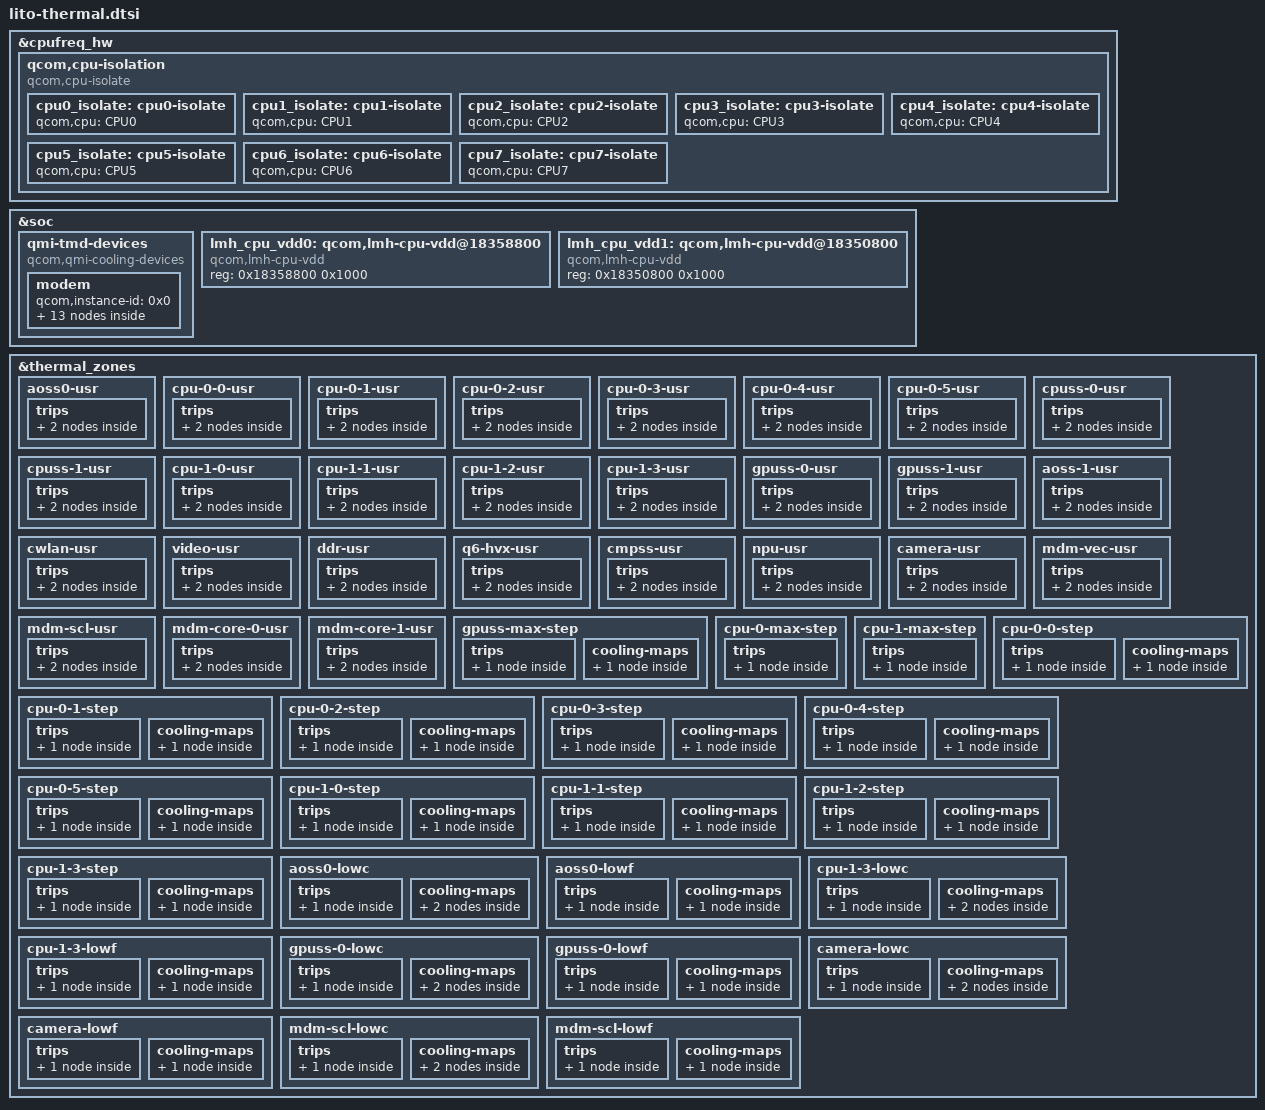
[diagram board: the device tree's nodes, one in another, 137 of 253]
#include <dt-bindings/thermal/thermal.h>

&cpufreq_hw {
	qcom,cpu-isolation {
		compatible = "qcom,cpu-isolate";
		cpu0_isolate: cpu0-isolate {
			qcom,cpu = <&CPU0>;
			#cooling-cells = <2>;
		};

		cpu1_isolate: cpu1-isolate {
			qcom,cpu = <&CPU1>;
			#cooling-cells = <2>;
		};

		cpu2_isolate: cpu2-isolate {
			qcom,cpu = <&CPU2>;
			#cooling-cells = <2>;
		};

		cpu3_isolate: cpu3-isolate {
			qcom,cpu = <&CPU3>;
			#cooling-cells = <2>;
		};

		cpu4_isolate: cpu4-isolate {
			qcom,cpu = <&CPU4>;
			#cooling-cells = <2>;
		};

		cpu5_isolate: cpu5-isolate {
			qcom,cpu = <&CPU5>;
			#cooling-cells = <2>;
		};

		cpu6_isolate: cpu6-isolate {
			qcom,cpu = <&CPU6>;
			#cooling-cells = <2>;
		};

		cpu7_isolate: cpu7-isolate {
			qcom,cpu = <&CPU7>;
			#cooling-cells = <2>;
		};
	};
};

&soc {
	qmi-tmd-devices {
		compatible = "qcom,qmi-cooling-devices";

		modem {
			qcom,instance-id = <0x0>;

			modem_pa: modem_pa {
				qcom,qmi-dev-name = "pa";
				#cooling-cells = <2>;
			};

			modem_proc: modem_proc {
				qcom,qmi-dev-name = "modem";
				#cooling-cells = <2>;
			};

			modem_current: modem_current {
				qcom,qmi-dev-name = "modem_current";
				#cooling-cells = <2>;
			};

			modem_skin: modem_skin {
				qcom,qmi-dev-name = "modem_skin";
				#cooling-cells = <2>;
			};

			modem_skin0: modem_skin0 {
				qcom,qmi-dev-name = "modem_skin0";
				#cooling-cells = <2>;
			};

			modem_skin1: modem_skin1 {
				qcom,qmi-dev-name = "modem_skin1";
				#cooling-cells = <2>;
			};

			modem_skin2: modem_skin2 {
				qcom,qmi-dev-name = "modem_skin2";
				#cooling-cells = <2>;
			};

			modem_skin3: modem_skin3 {
				qcom,qmi-dev-name = "modem_skin3";
				#cooling-cells = <2>;
			};

			modem_mmw0: modem_mmw0 {
				qcom,qmi-dev-name = "mmw0";
				#cooling-cells = <2>;
			};

			modem_mmw1: modem_mmw1 {
				qcom,qmi-dev-name = "mmw1";
				#cooling-cells = <2>;
			};

			modem_mmw2: modem_mmw2 {
				qcom,qmi-dev-name = "mmw2";
				#cooling-cells = <2>;
			};

			modem_mmw3: modem_mmw3 {
				qcom,qmi-dev-name = "mmw3";
				#cooling-cells = <2>;
			};

			modem_bcl: modem_bcl {
				qcom,qmi-dev-name = "vbatt_low";
				#cooling-cells = <2>;
			};
		};
	};

	lmh_cpu_vdd0: qcom,lmh-cpu-vdd@18358800 {
		compatible = "qcom,lmh-cpu-vdd";
		reg =  <0x18358800 0x1000>;
		#cooling-cells = <2>;
	};

	lmh_cpu_vdd1: qcom,lmh-cpu-vdd@18350800 {
		compatible = "qcom,lmh-cpu-vdd";
		reg =  <0x18350800 0x1000>;
		#cooling-cells = <2>;
	};

};

&thermal_zones {
	aoss0-usr {
		polling-delay-passive = <0>;
		polling-delay = <0>;
		thermal-governor = "user_space";
		thermal-sensors = <&tsens0 0>;
		wake-capable-sensor;
		trips {
			active-config0 {
				temperature = <125000>;
				hysteresis = <1000>;
				type = "passive";
			};

			reset-mon-config {
				temperature = <115000>;
				hysteresis = <1000>;
				type = "passive";
			};
		};
	};

	cpu-0-0-usr {
		polling-delay-passive = <0>;
		polling-delay = <0>;
		thermal-governor = "user_space";
		thermal-sensors = <&tsens0 1>;
		wake-capable-sensor;
		trips {
			active-config0 {
				temperature = <125000>;
				hysteresis = <1000>;
				type = "passive";
			};

			reset-mon-config {
				temperature = <115000>;
				hysteresis = <1000>;
				type = "passive";
			};
		};
	};

	cpu-0-1-usr {
		polling-delay-passive = <0>;
		polling-delay = <0>;
		thermal-governor = "user_space";
		thermal-sensors = <&tsens0 2>;
		wake-capable-sensor;
		trips {
			active-config0 {
				temperature = <125000>;
				hysteresis = <1000>;
				type = "passive";
			};

			reset-mon-config {
				temperature = <115000>;
				hysteresis = <1000>;
				type = "passive";
			};
		};
	};

	cpu-0-2-usr {
		polling-delay-passive = <0>;
		polling-delay = <0>;
		thermal-governor = "user_space";
		thermal-sensors = <&tsens0 3>;
		wake-capable-sensor;
		trips {
			active-config0 {
				temperature = <125000>;
				hysteresis = <1000>;
				type = "passive";
			};

			reset-mon-config {
				temperature = <115000>;
				hysteresis = <1000>;
				type = "passive";
			};
		};
	};

	cpu-0-3-usr {
		polling-delay-passive = <0>;
		polling-delay = <0>;
		thermal-sensors = <&tsens0 4>;
		thermal-governor = "user_space";
		wake-capable-sensor;
		trips {
			active-config0 {
				temperature = <125000>;
				hysteresis = <1000>;
				type = "passive";
			};

			reset-mon-config {
				temperature = <115000>;
				hysteresis = <1000>;
				type = "passive";
			};
		};
	};

	cpu-0-4-usr {
		polling-delay-passive = <0>;
		polling-delay = <0>;
		thermal-sensors = <&tsens0 5>;
		thermal-governor = "user_space";
		wake-capable-sensor;
		trips {
			active-config0 {
				temperature = <125000>;
				hysteresis = <1000>;
				type = "passive";
			};

			reset-mon-config {
				temperature = <115000>;
				hysteresis = <1000>;
				type = "passive";
			};
		};
	};

	cpu-0-5-usr {
		polling-delay-passive = <0>;
		polling-delay = <0>;
		thermal-sensors = <&tsens0 6>;
		thermal-governor = "user_space";
		wake-capable-sensor;
		trips {
			active-config0 {
				temperature = <125000>;
				hysteresis = <1000>;
				type = "passive";
			};

			reset-mon-config {
				temperature = <115000>;
				hysteresis = <1000>;
				type = "passive";
			};
		};
	};

	cpuss-0-usr {
		polling-delay-passive = <0>;
		polling-delay = <0>;
		thermal-sensors = <&tsens0 7>;
		thermal-governor = "user_space";
		wake-capable-sensor;
		trips {
			active-config0 {
				temperature = <125000>;
				hysteresis = <1000>;
				type = "passive";
			};

			reset-mon-config {
				temperature = <115000>;
				hysteresis = <1000>;
				type = "passive";
			};
		};
	};

	cpuss-1-usr {
		polling-delay-passive = <0>;
		polling-delay = <0>;
		thermal-sensors = <&tsens0 8>;
		thermal-governor = "user_space";
		wake-capable-sensor;
		trips {
			active-config0 {
				temperature = <125000>;
				hysteresis = <1000>;
				type = "passive";
			};

			reset-mon-config {
				temperature = <115000>;
				hysteresis = <1000>;
				type = "passive";
			};
		};
	};

	cpu-1-0-usr {
		polling-delay-passive = <0>;
		polling-delay = <0>;
		thermal-sensors = <&tsens0 9>;
		thermal-governor = "user_space";
		wake-capable-sensor;
		trips {
			active-config0 {
				temperature = <125000>;
				hysteresis = <1000>;
				type = "passive";
			};

			reset-mon-config {
				temperature = <115000>;
				hysteresis = <1000>;
				type = "passive";
			};
		};
	};

	cpu-1-1-usr {
		polling-delay-passive = <0>;
		polling-delay = <0>;
		thermal-sensors = <&tsens0 10>;
		thermal-governor = "user_space";
		wake-capable-sensor;
		trips {
			active-config0 {
				temperature = <125000>;
				hysteresis = <1000>;
				type = "passive";
			};

			reset-mon-config {
				temperature = <115000>;
				hysteresis = <1000>;
				type = "passive";
			};
		};
	};

	cpu-1-2-usr {
		polling-delay-passive = <0>;
		polling-delay = <0>;
		thermal-sensors = <&tsens0 11>;
		thermal-governor = "user_space";
		wake-capable-sensor;
		trips {
			active-config0 {
				temperature = <125000>;
				hysteresis = <1000>;
				type = "passive";
			};

			reset-mon-config {
				temperature = <115000>;
				hysteresis = <1000>;
				type = "passive";
			};
		};
	};

	cpu-1-3-usr {
		polling-delay-passive = <0>;
		polling-delay = <0>;
		thermal-sensors = <&tsens0 12>;
		thermal-governor = "user_space";
		wake-capable-sensor;
		trips {
			active-config0 {
				temperature = <125000>;
				hysteresis = <1000>;
				type = "passive";
			};

			reset-mon-config {
				temperature = <115000>;
				hysteresis = <1000>;
				type = "passive";
			};
		};
	};

	gpuss-0-usr {
		polling-delay-passive = <0>;
		polling-delay = <0>;
		thermal-sensors = <&tsens0 13>;
		thermal-governor = "user_space";
		wake-capable-sensor;
		trips {
			active-config0 {
				temperature = <125000>;
				hysteresis = <1000>;
				type = "passive";
			};

			reset-mon-config {
				temperature = <115000>;
				hysteresis = <1000>;
				type = "passive";
			};
		};
	};

	gpuss-1-usr {
		polling-delay-passive = <0>;
		polling-delay = <0>;
		thermal-sensors = <&tsens0 14>;
		thermal-governor = "user_space";
		wake-capable-sensor;
		trips {
			active-config0 {
				temperature = <125000>;
				hysteresis = <1000>;
				type = "passive";
			};

			reset-mon-config {
				temperature = <115000>;
				hysteresis = <1000>;
				type = "passive";
			};
		};
	};

	aoss-1-usr {
		polling-delay-passive = <0>;
		polling-delay = <0>;
		thermal-sensors = <&tsens1 0>;
		thermal-governor = "user_space";
		wake-capable-sensor;
		trips {
			active-config0 {
				temperature = <125000>;
				hysteresis = <1000>;
				type = "passive";
			};

			reset-mon-config {
				temperature = <115000>;
				hysteresis = <1000>;
				type = "passive";
			};
		};
	};

	cwlan-usr {
		polling-delay-passive = <0>;
		polling-delay = <0>;
		thermal-sensors = <&tsens1 1>;
		thermal-governor = "user_space";
		wake-capable-sensor;
		trips {
			active-config0 {
				temperature = <125000>;
				hysteresis = <1000>;
				type = "passive";
			};

			reset-mon-config {
				temperature = <115000>;
				hysteresis = <1000>;
				type = "passive";
			};
		};
	};

	video-usr {
		polling-delay-passive = <0>;
		polling-delay = <0>;
		thermal-sensors = <&tsens1 2>;
		thermal-governor = "user_space";
		wake-capable-sensor;
		trips {
			active-config0 {
				temperature = <125000>;
				hysteresis = <1000>;
				type = "passive";
			};

			reset-mon-config {
				temperature = <115000>;
				hysteresis = <1000>;
				type = "passive";
			};
		};
	};

	ddr-usr {
		polling-delay-passive = <0>;
		polling-delay = <0>;
		thermal-sensors = <&tsens1 3>;
		thermal-governor = "user_space";
		wake-capable-sensor;
		trips {
			active-config0 {
				temperature = <125000>;
				hysteresis = <1000>;
				type = "passive";
			};

			reset-mon-config {
				temperature = <115000>;
				hysteresis = <1000>;
				type = "passive";
			};
		};
	};

	q6-hvx-usr {
		polling-delay-passive = <0>;
		polling-delay = <0>;
		thermal-sensors = <&tsens1 4>;
		thermal-governor = "user_space";
		wake-capable-sensor;
		trips {
			active-config0 {
				temperature = <125000>;
				hysteresis = <1000>;
				type = "passive";
			};

			reset-mon-config {
				temperature = <115000>;
				hysteresis = <1000>;
				type = "passive";
			};
		};
	};

	cmpss-usr {
		polling-delay-passive = <0>;
		polling-delay = <0>;
		thermal-sensors = <&tsens1 5>;
		thermal-governor = "user_space";
		wake-capable-sensor;
		trips {
			active-config0 {
				temperature = <125000>;
				hysteresis = <1000>;
				type = "passive";
			};

			reset-mon-config {
				temperature = <115000>;
				hysteresis = <1000>;
				type = "passive";
			};
		};
	};

	npu-usr {
		polling-delay-passive = <0>;
		polling-delay = <0>;
		thermal-sensors = <&tsens1 6>;
		thermal-governor = "user_space";
		wake-capable-sensor;
		trips {
			active-config0 {
				temperature = <125000>;
				hysteresis = <1000>;
				type = "passive";
			};

			reset-mon-config {
				temperature = <115000>;
				hysteresis = <1000>;
				type = "passive";
			};
		};
	};

	camera-usr {
		polling-delay-passive = <0>;
		polling-delay = <0>;
		thermal-sensors = <&tsens1 7>;
		thermal-governor = "user_space";
		wake-capable-sensor;
		trips {
			active-config0 {
				temperature = <125000>;
				hysteresis = <1000>;
				type = "passive";
			};

			reset-mon-config {
				temperature = <115000>;
				hysteresis = <1000>;
				type = "passive";
			};
		};
	};

	mdm-vec-usr {
		polling-delay-passive = <0>;
		polling-delay = <0>;
		thermal-sensors = <&tsens1 8>;
		thermal-governor = "user_space";
		wake-capable-sensor;
		trips {
			active-config0 {
				temperature = <125000>;
				hysteresis = <1000>;
				type = "passive";
			};

			reset-mon-config {
				temperature = <115000>;
				hysteresis = <1000>;
				type = "passive";
			};
		};
	};

	mdm-scl-usr {
		polling-delay-passive = <0>;
		polling-delay = <0>;
		thermal-sensors = <&tsens1 9>;
		thermal-governor = "user_space";
		wake-capable-sensor;
		trips {
			active-config0 {
				temperature = <125000>;
				hysteresis = <1000>;
				type = "passive";
			};

			reset-mon-config {
				temperature = <115000>;
				hysteresis = <1000>;
				type = "passive";
			};
		};
	};

	mdm-core-0-usr {
		polling-delay-passive = <0>;
		polling-delay = <0>;
		thermal-sensors = <&tsens1 10>;
		thermal-governor = "user_space";
		wake-capable-sensor;
		trips {
			active-config0 {
				temperature = <125000>;
				hysteresis = <1000>;
				type = "passive";
			};

			reset-mon-config {
				temperature = <115000>;
				hysteresis = <1000>;
				type = "passive";
			};
		};
	};

	mdm-core-1-usr {
		polling-delay-passive = <0>;
		polling-delay = <0>;
		thermal-governor = "user_space";
		thermal-sensors = <&tsens1 11>;
		wake-capable-sensor;
		trips {
			active-config0 {
				temperature = <125000>;
				hysteresis = <1000>;
				type = "passive";
			};

			reset-mon-config {
				temperature = <115000>;
				hysteresis = <1000>;
				type = "passive";
			};
		};
	};

	gpuss-max-step {
		polling-delay-passive = <10>;
		polling-delay = <100>;
		thermal-governor = "step_wise";
		wake-capable-sensor;
		trips {
			gpu_trip0: gpu-trip0 {
				temperature = <95000>;
				hysteresis = <0>;
				type = "passive";
			};
		};

		cooling-maps {
			gpu_cdev {
				trip = <&gpu_trip0>;
				cooling-device = <&msm_gpu THERMAL_NO_LIMIT
							THERMAL_NO_LIMIT>;
			};
		};
	};

	cpu-0-max-step {
		polling-delay-passive = <0>;
		polling-delay = <0>;
		thermal-governor = "step_wise";
		wake-capable-sensor;
		trips {
			silver-trip {
				temperature = <120000>;
				hysteresis = <0>;
				type = "passive";
			};
		};
	};

	cpu-1-max-step {
		polling-delay-passive = <0>;
		polling-delay = <0>;
		thermal-governor = "step_wise";
		wake-capable-sensor;
		trips {
			gold-trip {
				temperature = <120000>;
				hysteresis = <0>;
				type = "passive";
			};
		};
	};

	cpu-0-0-step {
		polling-delay-passive = <0>;
		polling-delay = <0>;
		thermal-governor = "step_wise";
		thermal-sensors = <&tsens0 1>;
		wake-capable-sensor;
		trips {
			cpu00_config: cpu00-config {
				temperature = <110000>;
				hysteresis = <10000>;
				type = "passive";
			};
		};

		cooling-maps {
			cpu00_cdev {
				trip = <&cpu00_config>;
				cooling-device = <&cpu0_isolate 1 1>;
			};
		};
	};

	cpu-0-1-step {
		polling-delay-passive = <0>;
		polling-delay = <0>;
		thermal-governor = "step_wise";
		thermal-sensors = <&tsens0 2>;
		wake-capable-sensor;
		trips {
			cpu01_config: cpu01-config {
				temperature = <110000>;
				hysteresis = <10000>;
				type = "passive";
			};
		};

		cooling-maps {
			cpu01_cdev {
				trip = <&cpu01_config>;
				cooling-device = <&cpu1_isolate 1 1>;
			};
		};
	};

	cpu-0-2-step {
		polling-delay-passive = <0>;
		polling-delay = <0>;
		thermal-governor = "step_wise";
		thermal-sensors = <&tsens0 3>;
		wake-capable-sensor;
		trips {
			cpu02_config: cpu02-config {
				temperature = <110000>;
				hysteresis = <10000>;
				type = "passive";
			};
		};

		cooling-maps {
			cpu02_cdev {
				trip = <&cpu02_config>;
				cooling-device = <&cpu2_isolate 1 1>;
			};
		};
	};

	cpu-0-3-step {
		polling-delay-passive = <0>;
		polling-delay = <0>;
		thermal-sensors = <&tsens0 4>;
		thermal-governor = "step_wise";
		wake-capable-sensor;
		trips {
			cpu03_config: cpu03-config {
				temperature = <110000>;
				hysteresis = <10000>;
				type = "passive";
			};
		};

		cooling-maps {
			cpu03_cdev {
				trip = <&cpu03_config>;
				cooling-device = <&cpu3_isolate 1 1>;
			};
		};
	};

	cpu-0-4-step {
		polling-delay-passive = <0>;
		polling-delay = <0>;
		thermal-sensors = <&tsens0 5>;
		thermal-governor = "step_wise";
		wake-capable-sensor;
		trips {
			cpu04_config: cpu04-config {
				temperature = <110000>;
				hysteresis = <10000>;
				type = "passive";
			};
		};

		cooling-maps {
			cpu04_cdev {
				trip = <&cpu04_config>;
				cooling-device = <&cpu4_isolate 1 1>;
			};
		};
	};

	cpu-0-5-step {
		polling-delay-passive = <0>;
		polling-delay = <0>;
		thermal-sensors = <&tsens0 6>;
		thermal-governor = "step_wise";
		wake-capable-sensor;
		trips {
			cpu05_config: cpu05-config {
				temperature = <110000>;
				hysteresis = <10000>;
				type = "passive";
			};
		};

		cooling-maps {
			cpu05_cdev {
				trip = <&cpu05_config>;
				cooling-device = <&cpu5_isolate 1 1>;
			};
		};
	};

	cpu-1-0-step {
		polling-delay-passive = <0>;
		polling-delay = <0>;
		thermal-sensors = <&tsens0 9>;
		thermal-governor = "step_wise";
		wake-capable-sensor;
		trips {
			cpu10_config: cpu10-config {
				temperature = <110000>;
				hysteresis = <10000>;
				type = "passive";
			};
		};

		cooling-maps {
			cpu10_cdev {
				trip = <&cpu10_config>;
				cooling-device = <&cpu6_isolate 1 1>;
			};
		};
	};

	cpu-1-1-step {
		polling-delay-passive = <0>;
		polling-delay = <0>;
		thermal-sensors = <&tsens0 10>;
		thermal-governor = "step_wise";
		wake-capable-sensor;
		trips {
			cpu11_config: cpu11-config {
				temperature = <110000>;
				hysteresis = <10000>;
				type = "passive";
			};
		};

		cooling-maps {
			cpu11_cdev {
				trip = <&cpu11_config>;
				cooling-device = <&cpu6_isolate 1 1>;
			};
		};
	};

	cpu-1-2-step {
		polling-delay-passive = <0>;
		polling-delay = <0>;
		thermal-sensors = <&tsens0 11>;
		thermal-governor = "step_wise";
		wake-capable-sensor;
		trips {
			cpu12_config: cpu12-config {
				temperature = <110000>;
				hysteresis = <10000>;
				type = "passive";
			};
		};

		cooling-maps {
			cpu12_cdev {
				trip = <&cpu12_config>;
				cooling-device = <&cpu7_isolate 1 1>;
			};
		};
	};

	cpu-1-3-step {
		polling-delay-passive = <0>;
		polling-delay = <0>;
		thermal-sensors = <&tsens0 12>;
		thermal-governor = "step_wise";
		wake-capable-sensor;
		trips {
			cpu13_config: cpu13-config {
				temperature = <110000>;
				hysteresis = <10000>;
				type = "passive";
			};
		};

		cooling-maps {
			cpu13_cdev {
				trip = <&cpu13_config>;
				cooling-device = <&cpu7_isolate 1 1>;
			};
		};
	};

	aoss0-lowc {
		polling-delay-passive = <0>;
		polling-delay = <0>;
		thermal-sensors = <&tsens0 0>;
		thermal-governor = "low_limits_cap";
		wake-capable-sensor;
		tracks-low;
		trips {
			aoss0_cap: aoss0-trip {
				temperature = <5000>;
				hysteresis = <5000>;
				type = "passive";
			};
		};

		cooling-maps {
			lmh_cpu0_cdev {
				trip = <&aoss0_cap>;
				cooling-device = <&lmh_cpu_vdd0 1 1>;
			};

			lmh_cpu6_cdev {
				trip = <&aoss0_cap>;
				cooling-device = <&lmh_cpu_vdd1 1 1>;
			};
		};
	};

	aoss0-lowf {
		polling-delay-passive = <0>;
		polling-delay = <0>;
		thermal-sensors = <&tsens0 0>;
		thermal-governor = "low_limits_floor";
		wake-capable-sensor;
		tracks-low;
		trips {
			aoss0_trip: aoss0-trip {
				temperature = <5000>;
				hysteresis = <5000>;
				type = "passive";
			};
		};

		cooling-maps {
			lpi_cx_vdd_cdev {
				trip = <&aoss0_trip>;
				cooling-device = <&lpi_cx_cdev 0 0>;
			};
		};
	};

	cpu-1-3-lowc {
		polling-delay-passive = <0>;
		polling-delay = <0>;
		thermal-sensors = <&tsens0 12>;
		thermal-governor = "low_limits_cap";
		wake-capable-sensor;
		tracks-low;
		trips {
			cpu_1_3_cap: cpu-1-3-trip {
				temperature = <5000>;
				hysteresis = <5000>;
				type = "passive";
			};
		};

		cooling-maps {
			lmh_cpu0_cdev {
				trip = <&cpu_1_3_cap>;
				cooling-device = <&lmh_cpu_vdd0 1 1>;
			};

			lmh_cpu6_cdev {
				trip = <&cpu_1_3_cap>;
				cooling-device = <&lmh_cpu_vdd1 1 1>;
			};
		};
	};

	cpu-1-3-lowf {
		polling-delay-passive = <0>;
		polling-delay = <0>;
		thermal-sensors = <&tsens0 12>;
		thermal-governor = "low_limits_floor";
		wake-capable-sensor;
		tracks-low;
		trips {
			cpu_1_3_trip: cpu-1-3-trip {
				temperature = <5000>;
				hysteresis = <5000>;
				type = "passive";
			};
		};

		cooling-maps {
			lpi_cx_vdd_cdev {
				trip = <&cpu_1_3_trip>;
				cooling-device = <&lpi_cx_cdev 0 0>;
			};
		};
	};

	gpuss-0-lowc {
		polling-delay-passive = <0>;
		polling-delay = <0>;
		thermal-sensors = <&tsens0 13>;
		thermal-governor = "low_limits_cap";
		wake-capable-sensor;
		tracks-low;
		trips {
			gpuss0_cap: gpuss0-trip {
				temperature = <5000>;
				hysteresis = <5000>;
				type = "passive";
			};
		};

		cooling-maps {
			lmh_cpu0_cdev {
				trip = <&gpuss0_cap>;
				cooling-device = <&lmh_cpu_vdd0 1 1>;
			};

			lmh_cpu6_cdev {
				trip = <&gpuss0_cap>;
				cooling-device = <&lmh_cpu_vdd1 1 1>;
			};
		};
	};

	gpuss-0-lowf {
		polling-delay-passive = <0>;
		polling-delay = <0>;
		thermal-sensors = <&tsens0 13>;
		thermal-governor = "low_limits_floor";
		wake-capable-sensor;
		tracks-low;
		trips {
			gpuss0_trip: gpuss0-trip {
				temperature = <5000>;
				hysteresis = <5000>;
				type = "passive";
			};
		};

		cooling-maps {
			lpi_cx_vdd_cdev {
				trip = <&gpuss0_trip>;
				cooling-device = <&lpi_cx_cdev 0 0>;
			};
		};
	};

	camera-lowc {
		polling-delay-passive = <0>;
		polling-delay = <0>;
		thermal-sensors = <&tsens1 7>;
		thermal-governor = "low_limits_cap";
		wake-capable-sensor;
		tracks-low;
		trips {
			camera_cap: camera-trip {
				temperature = <5000>;
				hysteresis = <5000>;
				type = "passive";
			};
		};

		cooling-maps {
			lmh_cpu0_cdev {
				trip = <&camera_cap>;
				cooling-device = <&lmh_cpu_vdd0 1 1>;
			};

			lmh_cpu6_cdev {
				trip = <&camera_cap>;
				cooling-device = <&lmh_cpu_vdd1 1 1>;
			};
		};
	};

	camera-lowf {
		polling-delay-passive = <0>;
		polling-delay = <0>;
		thermal-sensors = <&tsens1 7>;
		thermal-governor = "low_limits_floor";
		wake-capable-sensor;
		tracks-low;
		trips {
			camera_trip: camera-trip {
				temperature = <5000>;
				hysteresis = <5000>;
				type = "passive";
			};
		};

		cooling-maps {
			lpi_cx_vdd_cdev {
				trip = <&camera_trip>;
				cooling-device = <&lpi_cx_cdev 0 0>;
			};
		};
	};

	mdm-scl-lowc {
		polling-delay-passive = <0>;
		polling-delay = <0>;
		thermal-sensors = <&tsens1 9>;
		thermal-governor = "low_limits_cap";
		wake-capable-sensor;
		tracks-low;
		trips {
			mdm_scl_cap: mdm-scl-trip {
				temperature = <5000>;
				hysteresis = <5000>;
				type = "passive";
			};
		};

		cooling-maps {
			lmh_cpu0_cdev {
				trip = <&mdm_scl_cap>;
				cooling-device = <&lmh_cpu_vdd0 1 1>;
			};

			lmh_cpu6_cdev {
				trip = <&mdm_scl_cap>;
				cooling-device = <&lmh_cpu_vdd1 1 1>;
			};
		};
	};

	mdm-scl-lowf {
		polling-delay-passive = <0>;
		polling-delay = <0>;
		thermal-sensors = <&tsens1 9>;
		thermal-governor = "low_limits_floor";
		wake-capable-sensor;
		tracks-low;
		trips {
			mdm_scl_trip: mdm-scl-trip {
				temperature = <5000>;
				hysteresis = <5000>;
				type = "passive";
			};
		};

		cooling-maps {
			lpi_cx_vdd_cdev {
				trip = <&mdm_scl_trip>;
				cooling-device = <&lpi_cx_cdev 0 0>;
			};
		};
	};
};
